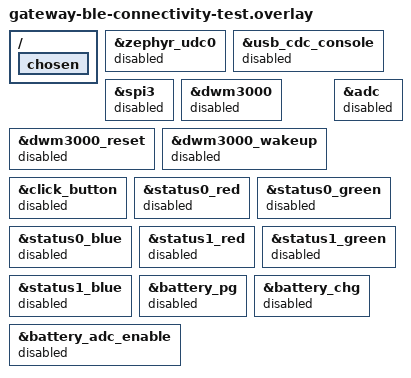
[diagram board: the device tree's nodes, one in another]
#include <zephyr/dt-bindings/gpio/gpio.h>

/ {
    chosen {
        /delete-property/ zephyr,console;
        /delete-property/ zephyr,shell-uart;
        /delete-property/ zephyr,uart-mcumgr;
        /delete-property/ zephyr,bt-mon-uart;
        /delete-property/ zephyr,bt-c2h-uart;
    };
};

&zephyr_udc0 {
    status = "disabled";
};

&usb_cdc_console {
    status = "disabled";
};

&spi3 {
    status = "disabled";
    /delete-property/ pinctrl-0;
    /delete-property/ pinctrl-1;
    /delete-property/ pinctrl-names;
};

&dwm3000 {
    status = "disabled";
};

&dwm3000_reset {
    status = "disabled";
};

&dwm3000_wakeup {
    status = "disabled";
};

&adc {
    status = "disabled";
};

&click_button {
    status = "disabled";
};

&status0_red {
    status = "disabled";
};

&status0_green {
    status = "disabled";
};

&status0_blue {
    status = "disabled";
};

&status1_red {
    status = "disabled";
};

&status1_green {
    status = "disabled";
};

&status1_blue {
    status = "disabled";
};

&battery_pg {
    status = "disabled";
};

&battery_chg {
    status = "disabled";
};

&battery_adc_enable {
    status = "disabled";
};
